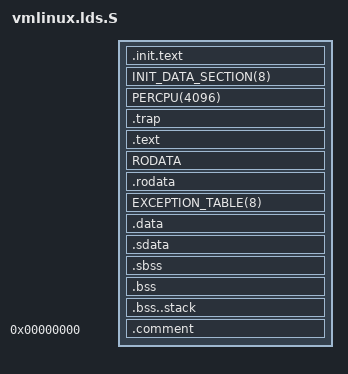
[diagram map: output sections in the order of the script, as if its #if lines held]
/* Copyright Statement:
 *
 * This software/firmware and related documentation ("MediaTek Software") are
 * protected under relevant copyright laws. The information contained herein
 * is confidential and proprietary to MediaTek Inc. and/or its licensors.
 * Without the prior written permission of MediaTek inc. and/or its licensors,
 * any reproduction, modification, use or disclosure of MediaTek Software,
 * and information contained herein, in whole or in part, shall be strictly prohibited.
 *
 * MediaTek Inc. (C) 2010. All rights reserved.
 *
 * BY OPENING THIS FILE, RECEIVER HEREBY UNEQUIVOCALLY ACKNOWLEDGES AND AGREES
 * THAT THE SOFTWARE/FIRMWARE AND ITS DOCUMENTATIONS ("MEDIATEK SOFTWARE")
 * RECEIVED FROM MEDIATEK AND/OR ITS REPRESENTATIVES ARE PROVIDED TO RECEIVER ON
 * AN "AS-IS" BASIS ONLY. MEDIATEK EXPRESSLY DISCLAIMS ANY AND ALL WARRANTIES,
 * EXPRESS OR IMPLIED, INCLUDING BUT NOT LIMITED TO THE IMPLIED WARRANTIES OF
 * MERCHANTABILITY, FITNESS FOR A PARTICULAR PURPOSE OR NONINFRINGEMENT.
 * NEITHER DOES MEDIATEK PROVIDE ANY WARRANTY WHATSOEVER WITH RESPECT TO THE
 * SOFTWARE OF ANY THIRD PARTY WHICH MAY BE USED BY, INCORPORATED IN, OR
 * SUPPLIED WITH THE MEDIATEK SOFTWARE, AND RECEIVER AGREES TO LOOK ONLY TO SUCH
 * THIRD PARTY FOR ANY WARRANTY CLAIM RELATING THERETO. RECEIVER EXPRESSLY ACKNOWLEDGES
 * THAT IT IS RECEIVER'S SOLE RESPONSIBILITY TO OBTAIN FROM ANY THIRD PARTY ALL PROPER LICENSES
 * CONTAINED IN MEDIATEK SOFTWARE. MEDIATEK SHALL ALSO NOT BE RESPONSIBLE FOR ANY MEDIATEK
 * SOFTWARE RELEASES MADE TO RECEIVER'S SPECIFICATION OR TO CONFORM TO A PARTICULAR
 * STANDARD OR OPEN FORUM. RECEIVER'S SOLE AND EXCLUSIVE REMEDY AND MEDIATEK'S ENTIRE AND
 * CUMULATIVE LIABILITY WITH RESPECT TO THE MEDIATEK SOFTWARE RELEASED HEREUNDER WILL BE,
 * AT MEDIATEK'S OPTION, TO REVISE OR REPLACE THE MEDIATEK SOFTWARE AT ISSUE,
 * OR REFUND ANY SOFTWARE LICENSE FEES OR SERVICE CHARGE PAID BY RECEIVER TO
 * MEDIATEK FOR SUCH MEDIATEK SOFTWARE AT ISSUE.
 */

/* ld script to make FRV Linux kernel
 * Written by Martin Mares <mj@atrey.karlin.mff.cuni.cz>;
 */
OUTPUT_FORMAT("elf32-frv", "elf32-frv", "elf32-frv")
OUTPUT_ARCH(frv)
ENTRY(_start)

#include <asm-generic/vmlinux.lds.h>
#include <asm/processor.h>
#include <asm/page.h>
#include <asm/cache.h>
#include <asm/thread_info.h>

jiffies = jiffies_64 + 4;

__page_offset = CONFIG_PAGE_OFFSET;	/* start of area covered by struct pages */
__kernel_image_start = __page_offset;	/* address at which kernel image resides */

SECTIONS
{
  . = __kernel_image_start;

  /* discardable initialisation code and data */
  . = ALIGN(PAGE_SIZE);			/* Init code and data */
  __init_begin = .;

  _sinittext = .;
  .init.text : {
	HEAD_TEXT
#ifndef CONFIG_DEBUG_INFO
	INIT_TEXT
	EXIT_TEXT
	EXIT_DATA
	*(.exitcall.exit)
#endif
  }
  _einittext = .;

  INIT_DATA_SECTION(8)
  PERCPU(4096)

  . = ALIGN(PAGE_SIZE);
  __init_end = .;

  .trap : {
	/* trap table management - read entry-table.S before modifying */
	. = ALIGN(8192);
	__trap_tables = .;
	*(.trap.user)
	*(.trap.kernel)
	. = ALIGN(4096);
	*(.trap.break)
  }

  /* Text and read-only data */
  . = ALIGN(4);
  _text = .;
  _stext = .;
  .text : {
	*(.text..start)
	*(.text..entry)
	*(.text..break)
	*(.text..tlbmiss)
	TEXT_TEXT
	SCHED_TEXT
	LOCK_TEXT
#ifdef CONFIG_DEBUG_INFO
	INIT_TEXT
	EXIT_TEXT
	*(.exitcall.exit)
#endif
	*(.fixup)
	*(.gnu.warning)
	*(.exitcall.exit)
	} = 0x9090

  _etext = .;			/* End of text section */

  RODATA

  .rodata : {
	*(.trap.vector)

	/* this clause must not be modified - the ordering and adjacency are imperative */
	__trap_fixup_tables = .;
	*(.trap.fixup.user .trap.fixup.kernel)

	}

  EXCEPTION_TABLE(8)

  _sdata = .;
  .data : {			/* Data */
	INIT_TASK_DATA(THREAD_SIZE)
	CACHELINE_ALIGNED_DATA(L1_CACHE_BYTES)
	DATA_DATA
	*(.data.*)
	EXIT_DATA
	CONSTRUCTORS
	}

  _edata = .;			/* End of data section */

  /* GP section */
  . = ALIGN(L1_CACHE_BYTES);
  _gp = . + 2048;
  PROVIDE (gp = _gp);

  .sdata : { *(.sdata .sdata.*) }

  /* BSS */
  . = ALIGN(L1_CACHE_BYTES);
  __bss_start = .;

  .sbss		: { *(.sbss .sbss.*) }
  .bss		: { *(.bss .bss.*) }
  .bss..stack	: { *(.bss) }

  __bss_stop = .;
  _end = . ;
  . = ALIGN(PAGE_SIZE);
  __kernel_image_end = .;

  STABS_DEBUG
  DWARF_DEBUG

  .comment 0 : { *(.comment) }

  DISCARDS
}

__kernel_image_size_no_bss = __bss_start - __kernel_image_start;
